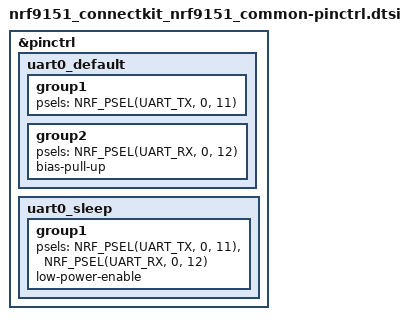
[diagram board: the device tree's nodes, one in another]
/*
 * Copyright (c) 2016-2025 Makerdiary <https://makerdiary.com>
 * SPDX-License-Identifier: Apache-2.0
 */

&pinctrl {
	uart0_default: uart0_default {
		group1 {
			psels = <NRF_PSEL(UART_TX, 0, 11)>;
		};
		group2 {
			psels = <NRF_PSEL(UART_RX, 0, 12)>;
			bias-pull-up;
		};
	};

	uart0_sleep: uart0_sleep {
		group1 {
			psels = <NRF_PSEL(UART_TX, 0, 11)>,
				<NRF_PSEL(UART_RX, 0, 12)>;
			low-power-enable;
		};
	};
};
